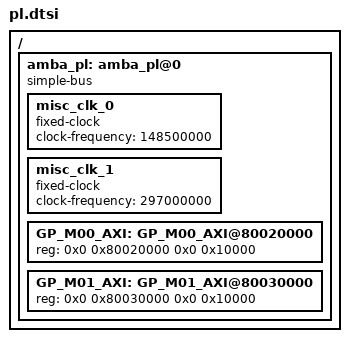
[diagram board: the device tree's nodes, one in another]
/*
 * CAUTION: This file is automatically generated by Xilinx.
 * Version: XSCT 2020.1
 * Today is: Wed Dec 29 20:15:44 2021
 */


/ {
	amba_pl: amba_pl@0 {
		#address-cells = <2>;
		#size-cells = <2>;
		compatible = "simple-bus";
		ranges ;
		// HDMI_v_hdmi_rx_ss_0: v_hdmi_rx_ss@80000000 {
		// 	clock-names = "s_axi_cpu_aclk", "link_clk", "s_axis_audio_aclk", "video_clk";
		// 	clocks = <&zynqmp_clk 73>, <&misc_clk_0>, <&misc_clk_1>, <&misc_clk_1>;
		// 	compatible = "xlnx,v-hdmi-rx-ss-3.1", "xlnx,v-hdmi-rx-ss-3.1";
		// 	interrupt-names = "irq";
		// 	interrupt-parent = <&gic>;
		// 	interrupts = <0 90 4>;
		// 	reg = <0x0 0x80000000 0x0 0x10000>;
		// };
		misc_clk_0: misc_clk_0 {
			#clock-cells = <0>;
			clock-frequency = <148500000>;
			compatible = "fixed-clock";
		};
		misc_clk_1: misc_clk_1 {
			#clock-cells = <0>;
			clock-frequency = <297000000>;
			compatible = "fixed-clock";
		};
		// HDMI_v_hdmi_tx_ss_0: v_hdmi_tx_ss@80010000 {
		// 	clock-names = "s_axi_cpu_aclk", "link_clk", "s_axis_audio_aclk", "video_clk";
		// 	clocks = <&zynqmp_clk 73>, <&misc_clk_0>, <&misc_clk_1>, <&misc_clk_1>;
		// 	compatible = "xlnx,v-hdmi-tx-ss-3.1", "xlnx,v-hdmi-tx-ss-3.1";
		// 	interrupt-names = "irq";
		// 	interrupt-parent = <&gic>;
		// 	interrupts = <0 92 4>;
		// 	reg = <0x0 0x80010000 0x0 0x10000>;
		// };
		// HDMI_vid_phy_controller_0: vid_phy_controller@80040000 {
		// 	clock-names = "mgtrefclk0_pad_p_in", "mgtrefclk0_pad_n_in", "mgtrefclk1_pad_p_in", "mgtrefclk1_pad_n_in", "vid_phy_tx_axi4s_aclk", "vid_phy_rx_axi4s_aclk", "vid_phy_sb_aclk", "vid_phy_axi4lite_aclk", "drpclk";
		// 	clocks = <&misc_clk_1>, <&misc_clk_1>, <&misc_clk_1>, <&misc_clk_1>, <&misc_clk_0>, <&misc_clk_0>, <&zynqmp_clk 73>, <&zynqmp_clk 73>, <&zynqmp_clk 73>;
		// 	compatible = "xlnx,vid-phy-controller-2.2", "xlnx,vid-phy-controller-2.1";
		// 	interrupt-names = "irq";
		// 	interrupt-parent = <&gic>;
		// 	interrupts = <0 91 4>;
		// 	reg = <0x0 0x80040000 0x0 0x10000>;
		// 	xlnx,hdmi-fast-switch = <1>;
		// 	xlnx,input-pixels-per-clock = <2>;
		// 	xlnx,nidru = <0>;
		// 	xlnx,nidru-refclk-sel = <0>;
		// 	xlnx,rx-no-of-channels = <3>;
		// 	xlnx,rx-pll-selection = <0>;
		// 	xlnx,rx-protocol = <1>;
		// 	xlnx,rx-refclk-sel = <1>;
		// 	xlnx,transceiver-type = <5>;
		// 	xlnx,transceiver-width = <2>;
		// 	xlnx,tx-buffer-bypass = <1>;
		// 	xlnx,tx-no-of-channels = <3>;
		// 	xlnx,tx-pll-selection = <6>;
		// 	xlnx,tx-protocol = <1>;
		// 	xlnx,tx-refclk-sel = <0>;
		// 	xlnx,use-gt-ch4-hdmi = <0>;
		// 	vphy_lane0: vphy_lane@0 {
		// 		#phy-cells = <4>;
		// 	};
		// 	vphy_lane1: vphy_lane@1 {
		// 		#phy-cells = <4>;
		// 	};
		// 	vphy_lane2: vphy_lane@2 {
		// 		#phy-cells = <4>;
		// 	};
		// 	vphy_lane3: vphy_lane@3 {
		// 		#phy-cells = <4>;
		// 	};
		// };
		// core_axi_iic_0: i2c@80050000 {
		// 	#address-cells = <1>;
		// 	#size-cells = <0>;
		// 	clock-names = "s_axi_aclk";
		// 	clocks = <&zynqmp_clk 73>;
		// 	compatible = "xlnx,axi-iic-2.0", "xlnx,xps-iic-2.00.a";
		// 	reg = <0x0 0x80050000 0x0 0x10000>;
		// };
		GP_M00_AXI: GP_M00_AXI@80020000 {
			/* This is a external AXI interface, user may need to update the entries */
			reg = <0x0 0x80020000 0x0 0x10000>;
		};
		GP_M01_AXI: GP_M01_AXI@80030000 {
			/* This is a external AXI interface, user may need to update the entries */
			reg = <0x0 0x80030000 0x0 0x10000>;
		};
	};
};
